VERSION ""

NS_ :

BS_:

BU_: BMS MC PDM D153 VCU
VAL_TABLE_ ReadyToDriveStateEnumeration 3 "Ready" 2 "Alarm Sounding" 1 "Not Ready" 0 "Fault" ;
VAL_TABLE_ ReadyToDriveFaultEnumeration 5 "Throttle Pedal Engaged" 4 "Brakes Disengaged" 3 "Tractive System Inactive" 2 "No Faults" 1 "Brake Sensor Configuration Error" 0 "Unknown Fault" ;

BO_ 123 VCU_vehicleInfo100Hz: 8 VCU
 SG_ VCU_vehicleInfo100HzMux M : 7|8@0+ (1,0) [0|255] "" Vector__XXX
 SG_ VCU_yawRate m1 : 47|16@0- (0.01,-100) [-100|100] "deg/s" Vector__XXX
 SG_ VCU_rollRate m1 : 31|16@0- (0.01,-100) [-100|100] "deg/s" Vector__XXX
 SG_ VCU_pitchRate m1 : 15|16@0- (0.01,-100) [-100|100] "deg/s" Vector__XXX
 SG_ VCU_verticalAcceleration m0 : 47|16@0+ (0.001,-50) [-50|50] "m/s2" Vector__XXX
 SG_ VCU_longitudinalAcceleration m0 : 31|16@0+ (0.001,-50) [-50|50] "m/s2" Vector__XXX
 SG_ VCU_lateralAcceleration m0 : 15|16@0+ (0.001,-50) [-50|50] "m/s2" Vector__XXX

BO_ 165 INV_motorPositionInfo: 8 BMS
 SG_ INV_motorSpeed : 23|16@0- (1,0) [0|39000] "deg/s"  D153

BO_ 167 INV_voltageInfo: 8 MC
 SG_ INV_dcBusVoltage : 7|16@0- (1,0) [0|600] ""  D153

BO_ 170 INV_internalStates: 8 MC
 SG_ INV_limitCoolantDerating : 6|1@0- (1,-1) [-1|1] ""  D153
 SG_ INV_bmsTorqueLimiting : 7|1@0- (1,-1) [-1|1] ""  D153

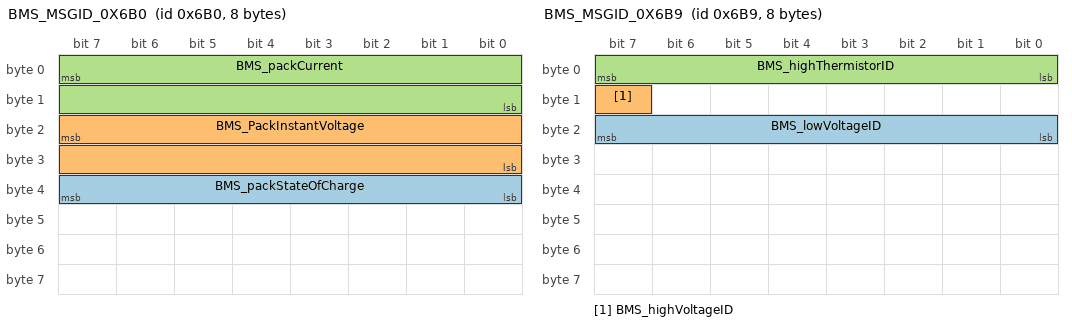
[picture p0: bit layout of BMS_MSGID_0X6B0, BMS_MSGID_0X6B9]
BO_ 1712 BMS_MSGID_0X6B0: 8 BMS
 SG_ BMS_packStateOfCharge : 39|8@0- (1,0) [0|1] "Ratio"  D153
 SG_ BMS_PackInstantVoltage : 23|16@0- (0.01,0) [0|600] "Volts"  D153
 SG_ BMS_packCurrent : 7|16@0- (0.01,0) [0|200] "Amps"  D153

BO_ 1714 BMS_MSGID_0X6B2: 8 BMS
 SG_ BMS_failsafeStatuses : 7|8@0- (1,0) [1|180] ""  D153

BO_ 54 BMS_MSGID_0X36_CELLBCAST: 8 BMS
 SG_ BMS_cellBalancing : 7|8@0- (1,0) [1|180] ""  D153

BO_ 1721 BMS_MSGID_0X6B9: 8 BMS
 SG_ BMS_lowVoltageID : 23|8@0- (1,0) [1|180] ""  D153
 SG_ BMS_highVoltageID : 15|1@0- (1,0) [1|180] ""  D153
 SG_ BMS_highThermistorID : 7|8@0- (1,0) [1|180] ""  D153

BO_ 1715 BMS_MSGID_0X6B3: 8 BMS
 SG_ BMS_lowThermistorID : 7|8@0- (1,0) [1|180] ""  D153

BO_ 1608 VCU_warning10Hz: 8 VCU
 SG_ VCU_mcCoolantFlowRateDiag m1 : 53|2@0- (1,0) [0|1] ""  D153
 SG_ VCU_gpsDiag m2 : 11|2@0- (1,0) [0|1] ""  D153
 SG_ VCU_CANBus3Diagnostic m2 : 15|2@0- (1,0) [0|1] ""  D153
 SG_ VCU_CANBus2Diagnostic m1 : 57|2@0- (1,0) [0|1] ""  D153
 SG_ VCU_CANBus1Diagnostic m1 : 59|2@0- (1,0) [0|1] ""  D153
 SG_ VCU_brakePressureSensorDiag m1 : 61|2@0- (1,0) [0|1] ""  D153
 SG_ VCU_warning10HzMux M : 7|8@0+ (1,0) [0|255] ""  D153
 SG_ VCU_tsOverPowerWarning m1 : 15|2@0- (1,0) [0|1] ""  D153
 SG_ VCU_throttlePedalSensorDiag m1 : 63|2@0- (1,0) [0|1] ""  D153
 SG_ VCU_rs232Diag m2 : 13|2@0- (1,0) [0|1] ""  D153
 SG_ VCU_radiatorCoolantFlowRateDiag m1 : 49|2@0- (1,0) [0|1] ""  D153
 SG_ VCU_radCoolantTempOutWarning m0 : 17|2@0- (1,0) [0|1] ""  D153
 SG_ VCU_radCoolantTempOutDiag m1 : 25|2@0- (1,0) [0|1] ""  D153
 SG_ VCU_radCoolantTempInWarning m0 : 19|2@0- (1,0) [0|1] ""  D153
 SG_ VCU_radCoolantTempInDiag m1 : 27|2@0- (1,0) [0|1] ""  D153
 SG_ VCU_radCoolantPressOutWarning m0 : 33|2@0- (1,0) [0|1] ""  D153
 SG_ VCU_radCoolantPressOutDiag m1 : 41|2@0- (1,0) [0|1] ""  D153
 SG_ VCU_radCoolantPressInWarning m0 : 35|2@0- (1,0) [0|1] ""  D153
 SG_ VCU_radCoolantPressInDiag m1 : 43|2@0- (1,0) [0|1] ""  D153
 SG_ VCU_radCoolantFlowRateWarning m0 : 41|2@0- (1,0) [0|1] ""  D153
 SG_ VCU_pedalPlausFaultWarning m1 : 11|2@0- (1,0) [0|1] ""  D153
 SG_ VCU_motorTorqueLimitWarning m2 : 31|2@0- (1,0) [0|1] ""  D153
 SG_ VCU_motorSpeedLimitWarning m2 : 17|2@0- (1,0) [0|1] ""  D153
 SG_ VCU_motorOverVoltWarning m0 : 53|2@0- (1,0) [0|1] ""  D153
 SG_ VCU_motorOverSpeedWarning m0 : 55|2@0- (1,0) [0|1] ""  D153
 SG_ VCU_motorOverCurrentWarning m0 : 51|2@0- (1,0) [0|1] ""  D153
 SG_ VCU_motorCoolantTempOutWarning m0 : 13|2@0- (1,0) [0|1] ""  D153
 SG_ VCU_motorCoolantTempOutDiag m1 : 21|2@0- (1,0) [0|1] ""  D153
 SG_ VCU_motorCoolantTempInWarning m0 : 15|2@0- (1,0) [0|1] ""  D153
 SG_ VCU_motorCoolantTempInDiag m1 : 23|2@0- (1,0) [0|1] ""  D153
 SG_ VCU_motorCoolantPressOutWarning m0 : 29|2@0- (1,0) [0|1] ""  D153
 SG_ VCU_motorCoolantPressOutDiag m1 : 37|2@0- (1,0) [0|1] ""  D153
 SG_ VCU_motorCoolantPressInWarning m0 : 31|2@0- (1,0) [0|1] ""  D153
 SG_ VCU_motorCoolantPressInDiag m1 : 39|2@0- (1,0) [0|1] ""  D153
 SG_ VCU_motorCoolantFlowRateWarning m0 : 47|2@0- (1,0) [0|1] ""  D153
 SG_ VCU_motorCoolantFlowRateDiag m1 : 55|2@0- (1,0) [0|1] ""  D153
 SG_ VCU_mcOverVoltWarning m0 : 49|2@0- (1,0) [0|1] ""  D153
 SG_ VCU_mcOverCurrentWarning m0 : 63|2@0- (1,0) [0|1] ""  D153
 SG_ VCU_mcCoolantTempOutWarning m0 : 9|2@0- (1,0) [0|1] ""  D153
 SG_ VCU_mcCoolantTempOutDiag m1 : 17|2@0- (1,0) [0|1] ""  D153
 SG_ VCU_mcCoolantTempInWarning m0 : 11|2@0- (1,0) [0|1] ""  D153
 SG_ VCU_mcCoolantTempInDiag m1 : 19|2@0- (1,0) [0|1] ""  D153
 SG_ VCU_mcCoolantPressOutWarning m0 : 25|2@0- (1,0) [0|1] ""  D153
 SG_ VCU_mcCoolantPressOutDiag m1 : 33|2@0- (1,0) [0|1] ""  D153
 SG_ VCU_mcCoolantPressInWarning m0 : 27|2@0- (1,0) [0|1] ""  D153
 SG_ VCU_mcCoolantPressInDiag m1 : 35|2@0- (1,0) [0|1] ""  D153
 SG_ VCU_mcCoolantFlowRateWarning m0 : 45|2@0- (1,0) [0|1] ""  D153
 SG_ VCU_mcCANTimeoutWarning m2 : 9|2@0- (1,0) [0|1] ""  D153
 SG_ VCU_batteryUnderVoltWarning m1 : 13|2@0- (1,0) [0|1] ""  D153
 SG_ VCU_accuUnderVoltWarning m0 : 59|2@0- (1,0) [0|1] ""  D153
 SG_ VCU_accuOverVoltWarning m0 : 61|2@0- (1,0) [0|1] ""  D153
 SG_ VCU_accuOverCurrentWarning m0 : 57|2@0- (1,0) [0|1] ""  D153
 SG_ VCU_accumulatorTempWarning m1 : 9|2@0- (1,0) [0|1] ""  D153
 SG_ VCU_accuIMDLightWarning m2 : 21|2@0- (1,0) [0|1] ""  D153
 SG_ VCU_accuHVILWarning m2 : 19|2@0- (1,0) [0|1] ""  D153
 SG_ VCU_accuCoolantTempOutWarning m0 : 21|2@0- (1,0) [0|1] ""  D153
 SG_ VCU_accuCoolantTempOutDiag m1 : 29|2@0- (1,0) [0|1] ""  D153
 SG_ VCU_accuCoolantTempInWarning m0 : 23|2@0- (1,0) [0|1] ""  D153
 SG_ VCU_accuCoolantTempInDiag m1 : 31|2@0- (1,0) [0|1] ""  D153
 SG_ VCU_accuCoolantPressOutWarning m0 : 37|2@0- (1,0) [0|1] ""  D153
 SG_ VCU_accuCoolantPressOutDiag m1 : 45|2@0- (1,0) [0|1] ""  D153
 SG_ VCU_accuCoolantPressInWarning m0 : 39|2@0- (1,0) [0|1] ""  D153
 SG_ VCU_accuCoolantPressInDiag m1 : 47|2@0- (1,0) [0|1] ""  D153
 SG_ VCU_accuCoolantFlowRateWarning m0 : 43|2@0- (1,0) [0|1] ""  D153
 SG_ VCU_accuCoolantFlowRateDiag m1 : 51|2@0- (1,0) [0|1] ""  D153
 SG_ VCU_accuCANTimeoutWarning m2 : 23|2@0- (1,0) [0|1] ""  D153

BO_ 1280 PDM_pdmCurrentTotal: 8 PDM
 SG_ PDM_pdmTotalCurrent : 7|8@0- (1,0) [0|100] "Amps"  D153

BO_ 1606 VCU_vehicleState10Hz: 8 VCU
 SG_ VCU_vehicleState10HzMux M : 7|8@0+ (1,0) [0|255] "" Vector__XXX
 SG_ VCU_tsalState m1 : 39|8@0+ (1,0) [0|9] ""  D153
 SG_ VCU_throttlePedalPlausCheckState m1 : 23|8@0+ (1,-3) [-3|9] ""  D153
 SG_ VCU_throttleMapAimSwitch m0 : 23|8@0+ (1,-1) [-1|9] ""  D153
 SG_ VCU_readyToDriveState m1 : 55|8@0+ (1,-1) [-1|9] ""  D153
 SG_ VCU_readyToDriveFault m1 : 31|8@0+ (1,-2) [-2|9] ""  D153
 SG_ VCU_mcDiagCANTimeout m2 : 39|8@0+ (1,0) [0|255] "ms"  D153
 SG_ VCU_launchAim m0 : 31|8@0+ (1,-1) [-1|9] ""  D153
 SG_ VCU_launchState m2 : 15|8@0+ (1,0) [0|9] ""  D153
 SG_ VCU_driverMarkerSwitch m0 : 39|1@0- (1,0) [0|1] ""  D153
 SG_ VCU_dashScreenAimSwitch m0 : 15|8@0+ (1,-1) [-1|9] ""  D153
 SG_ VCU_accuDiagCANTimeout m2 : 23|16@0- (1,0) [0|10000] "ms"  D153
 SG_ VCU_warningSource m1 : 15|7@0- (1,0) [0|65] ""  D153

BO_ 1604 VCU_vehicleInfo10Hz: 8 VCU
 SG_ VCU_vechicleInfo10HzMux M : 7|8@0+ (1,0) [0|255] ""  D153
 SG_ VCU_vehicleSpeed m0 : 15|16@0- (0.01,0) [0|100] "m/s"  D153
 SG_ VCU_vcuBatteryVoltage m1 : 31|8@0- (1,0) [0|28] "Volts"  D153
 SG_ VCU_throttlePedalTorqueMap m0 : 31|16@0+ (0.1,-500) [-500|500] "Newton-Meter"  D153
 SG_ VCU_brakeBiasAim m0 : 47|8@0- (1,0) [0|1] "Ratio"  D153
 SG_ VCU_accumEstimatedPower m1 : 15|16@0- (1,0) [0|1200] "Watt"  D153

BO_ 1602 VCU_componentTemp10Hz: 8 VCU
 SG_ VCU_motorTemp m0 : 15|16@0+ (0.1,-3276) [-3276|3276] "Celcius"  D153
 SG_ VCU_mcTempHotSpot m0 : 47|16@0+ (1,-3276) [-3276|3276] "Celcius"  D153
 SG_ VCU_mcTempCoolant m0 : 31|16@0+ (0.1,-3276) [-3276|3276] "Celcius"  D153
 SG_ VCU_accuLowestTemp m2 : 31|16@0+ (0.1,-3276) [-3276|3276] "Celcius"  D153
 SG_ VCU_accuInternalTemp m1 : 15|16@0+ (0.1,-3276) [-3276|3276] "Celcius"  D153
 SG_ VCU_accuHighestTemp m2 : 15|16@0+ (0.1,-3276) [-3276|3276] "Celcius"  D153
 SG_ VCU_accuAverageTemp m1 : 31|16@0+ (0.1,-3276) [-3276|3276] "Celcius"  D153
 SG_ VCU_componentTemp10HzMux M : 7|8@0+ (1,0) [0|255] ""  D153

BO_ 1872 VCU_tireInfo10Hz: 8 VCU
 SG_ VCU_tireInfo10HzMux M : 7|8@0+ (1,0) [0|255] ""  D153
 SG_ VCU_avgTireTempRR m1 : 31|16@0- (0.1,0) [0|100] "Celcius"  D153
 SG_ VCU_avgTireTempRL m1 : 15|16@0- (0.1,0) [0|100] "Celcius"  D153
 SG_ VCU_avgTireTempFR m0 : 31|16@0- (0.1,0) [0|100] "Celcius"  D153
 SG_ VCU_avgTireTempFL m0 : 15|16@0- (0.1,0) [0|100] "Celcius"  D153

BO_ 1600 VCU_coolantInfo10Hz: 8 VCU
 SG_ VCU_radCoolantTempOut m3 : 55|8@0+ (1,-20) [-20|235] "Celcius"  D153
 SG_ VCU_radCoolantTempIn m3 : 47|8@0+ (1,-20) [-20|235] "Celcius"  D153
 SG_ VCU_radCoolantPressOut m3 : 31|16@0- (0.1,0) [0|300000] "Pa"  D153
 SG_ VCU_radCoolantPressIn m3 : 15|16@0- (0.1,0) [0|300000] "Pa"  D153
 SG_ VCU_motorCoolantTempOut m1 : 55|8@0+ (1,-20) [-20|235] "Celcius"  D153
 SG_ VCU_motorCoolantTempIn m1 : 47|8@0+ (1,-20) [-20|235] "Celcius"  D153
 SG_ VCU_motorCoolantPressOut m1 : 31|16@0- (0.1,0) [0|300000] "Pa"  D153
 SG_ VCU_motorCoolantPressIn m1 : 15|16@0- (0.1,0) [0|300000] "Pa"  D153
 SG_ VCU_motorCoolantFlowRate m4 : 15|16@0- (0.1,0) [0|100] "L/min"  D153
 SG_ VCU_mcCoolantTempOut m2 : 55|8@0+ (1,-20) [-20|235] "Celcius"  D153
 SG_ VCU_mcCoolantTempIn m2 : 47|8@0+ (1,-20) [-20|235] "Celcius"  D153
 SG_ VCU_mcCoolantPressOut m2 : 31|16@0- (0.1,0) [0|300000] "Pa"  D153
 SG_ VCU_mcCoolantPressIn m2 : 15|16@0- (0.1,0) [0|300000] "Pa"  D153
 SG_ VCU_mcCoolantFlowRate m4 : 31|16@0- (0.1,0) [0|100] "L/min"  D153
 SG_ VCU_accuCoolantTempOut m0 : 55|8@0+ (1,-20) [-20|235] "Celcius "  D153
 SG_ VCU_accuCoolantTempIn m0 : 47|8@0+ (1,-20) [-20|235] "Celcius"  D153
 SG_ VCU_accuCoolantPressOut m0 : 31|16@0- (0.1,0) [0|300000] "Pa"  D153
 SG_ VCU_coolantInfo10HzMux M : 7|8@0+ (1,0) [0|255] ""  D153
 SG_ VCU_accuCoolantPressIn m0 : 15|16@0- (0.1,0) [0|300000] "Pa"  D153

BA_DEF_ BO_  "GenMsgCycleTime" INT 0 100000;
BA_DEF_  "BusType" STRING ;
BA_DEF_DEF_  "GenMsgCycleTime" 0;
BA_DEF_DEF_  "BusType" "CAN";
BA_ "GenMsgCycleTime" BO_ 123 10;
BA_ "GenMsgCycleTime" BO_ 1608 100;
BA_ "GenMsgCycleTime" BO_ 1606 100;
BA_ "GenMsgCycleTime" BO_ 1604 100;
BA_ "GenMsgCycleTime" BO_ 1602 100;
BA_ "GenMsgCycleTime" BO_ 1872 100;
BA_ "GenMsgCycleTime" BO_ 1600 100;
VAL_ 1606 VCU_readyToDriveState 3 "Ready" 2 "Alarm Sounding" 1 "Not Ready" 0 "Fault" ;
VAL_ 1606 VCU_readyToDriveFault 5 "Throttle Pedal Engaged" 4 "Brakes Disengaged" 3 "Tractive System Inactive" 2 "No Faults" 1 "Brake Sensor Configuration Error" 0 "Unknown Fault" ;
